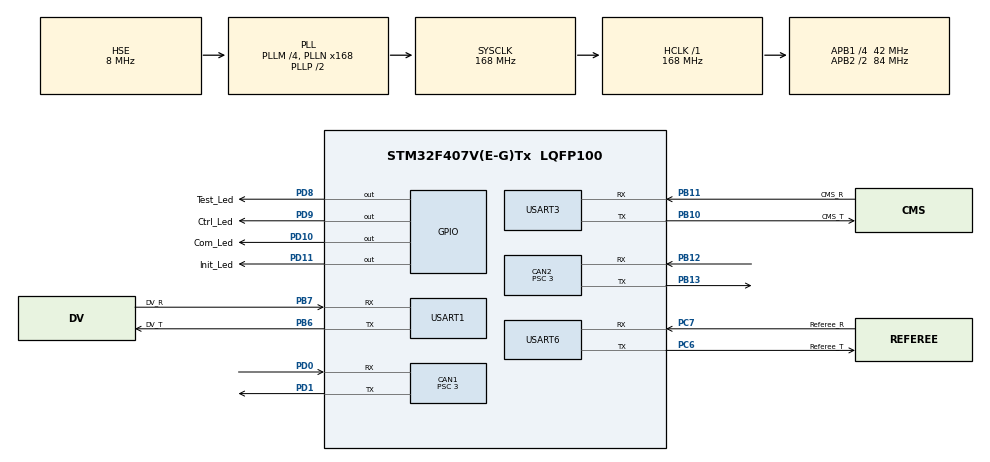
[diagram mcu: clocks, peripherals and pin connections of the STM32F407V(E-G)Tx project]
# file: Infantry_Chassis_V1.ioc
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CAN1.BS1=CAN_BS1_10TQ
CAN1.BS2=CAN_BS2_3TQ
CAN1.CalculateBaudRate=1000000
CAN1.CalculateTimeBit=1000
CAN1.CalculateTimeQuantum=71.42857142857143
CAN1.Prescaler=3
CAN2.BS1=CAN_BS1_10TQ
CAN2.BS2=CAN_BS2_3TQ
CAN2.CalculateBaudRate=1000000
CAN2.CalculateTimeBit=1000
CAN2.CalculateTimeQuantum=71.42857142857143
CAN2.Prescaler=3
Dma.Request0=USART3_RX
Dma.Request1=USART3_TX
Dma.Request2=USART6_RX
Dma.Request3=USART6_TX
Dma.Request4=USART1_TX
Dma.Request5=USART1_RX
Dma.USART1_RX.5.Direction=DMA_PERIPH_TO_MEMORY
Dma.USART1_RX.5.FIFOMode=DMA_FIFOMODE_DISABLE
Dma.USART1_RX.5.Instance=DMA2_Stream2
Dma.USART1_RX.5.MemDataAlignment=DMA_MDATAALIGN_BYTE
Dma.USART1_RX.5.MemInc=DMA_MINC_ENABLE
Dma.USART1_RX.5.Mode=DMA_NORMAL
Dma.USART1_RX.5.PeriphDataAlignment=DMA_PDATAALIGN_BYTE
Dma.USART1_RX.5.PeriphInc=DMA_PINC_DISABLE
Dma.USART1_RX.5.Priority=DMA_PRIORITY_LOW
Dma.USART1_TX.4.Direction=DMA_MEMORY_TO_PERIPH
Dma.USART1_TX.4.FIFOMode=DMA_FIFOMODE_DISABLE
Dma.USART1_TX.4.Instance=DMA2_Stream7
Dma.USART1_TX.4.MemDataAlignment=DMA_MDATAALIGN_BYTE
Dma.USART1_TX.4.MemInc=DMA_MINC_ENABLE
Dma.USART1_TX.4.Mode=DMA_NORMAL
Dma.USART1_TX.4.PeriphDataAlignment=DMA_PDATAALIGN_BYTE
Dma.USART1_TX.4.PeriphInc=DMA_PINC_DISABLE
Dma.USART1_TX.4.Priority=DMA_PRIORITY_LOW
Dma.USART3_RX.0.Direction=DMA_PERIPH_TO_MEMORY
Dma.USART3_RX.0.FIFOMode=DMA_FIFOMODE_DISABLE
Dma.USART3_RX.0.Instance=DMA1_Stream1
Dma.USART3_RX.0.MemDataAlignment=DMA_MDATAALIGN_BYTE
Dma.USART3_RX.0.MemInc=DMA_MINC_ENABLE
Dma.USART3_RX.0.Mode=DMA_NORMAL
Dma.USART3_RX.0.PeriphDataAlignment=DMA_PDATAALIGN_BYTE
Dma.USART3_RX.0.PeriphInc=DMA_PINC_DISABLE
Dma.USART3_RX.0.Priority=DMA_PRIORITY_LOW
Dma.USART3_TX.1.Direction=DMA_MEMORY_TO_PERIPH
Dma.USART3_TX.1.FIFOMode=DMA_FIFOMODE_DISABLE
Dma.USART3_TX.1.Instance=DMA1_Stream3
Dma.USART3_TX.1.MemDataAlignment=DMA_MDATAALIGN_BYTE
Dma.USART3_TX.1.MemInc=DMA_MINC_ENABLE
Dma.USART3_TX.1.Mode=DMA_NORMAL
Dma.USART3_TX.1.PeriphDataAlignment=DMA_PDATAALIGN_BYTE
Dma.USART3_TX.1.PeriphInc=DMA_PINC_DISABLE
Dma.USART3_TX.1.Priority=DMA_PRIORITY_LOW
Dma.USART6_RX.2.Direction=DMA_PERIPH_TO_MEMORY
Dma.USART6_RX.2.FIFOMode=DMA_FIFOMODE_DISABLE
Dma.USART6_RX.2.Instance=DMA2_Stream1
Dma.USART6_RX.2.MemDataAlignment=DMA_MDATAALIGN_BYTE
Dma.USART6_RX.2.MemInc=DMA_MINC_ENABLE
Dma.USART6_RX.2.Mode=DMA_NORMAL
Dma.USART6_RX.2.PeriphDataAlignment=DMA_PDATAALIGN_BYTE
Dma.USART6_RX.2.PeriphInc=DMA_PINC_DISABLE
Dma.USART6_RX.2.Priority=DMA_PRIORITY_LOW
Dma.USART6_TX.3.Direction=DMA_MEMORY_TO_PERIPH
Dma.USART6_TX.3.FIFOMode=DMA_FIFOMODE_DISABLE
Dma.USART6_TX.3.Instance=DMA2_Stream6
Dma.USART6_TX.3.MemDataAlignment=DMA_MDATAALIGN_BYTE
Dma.USART6_TX.3.MemInc=DMA_MINC_ENABLE
Dma.USART6_TX.3.Mode=DMA_NORMAL
Dma.USART6_TX.3.PeriphDataAlignment=DMA_PDATAALIGN_BYTE
Dma.USART6_TX.3.PeriphInc=DMA_PINC_DISABLE
Dma.USART6_TX.3.Priority=DMA_PRIORITY_LOW
FREERTOS.Tasks01=defaultTask,0,128,StartDefaultTask,Default,NULL,Dynamic,NULL,NULL;Chassis,0,512,ChassisTask,As external,NULL,Dynamic,NULL,NULL;Referee,0,512,RefereeTask,As external,NULL,Dynamic,NULL,NULL;DataVsualizatio,0,512,DVTask,As external,NULL,Dynamic,NULL,NULL;Communication,0,512,ComTask,As external,NULL,Dynamic,NULL,NULL;CanSend,3,512,CanSendTask,As external,NULL,Dynamic,NULL,NULL
Mcu.Family=STM32F4
Mcu.Name=STM32F407V(E-G)Tx
Mcu.Package=LQFP100
NVIC.CAN1_RX0_IRQn=true\:5\:0\:false\:false\:true\:true\:true\:true
NVIC.CAN2_RX0_IRQn=true\:5\:0\:false\:false\:true\:true\:true\:true
NVIC.DMA1_Stream1_IRQn=true\:5\:0\:false\:false\:true\:true\:false\:true
NVIC.DMA1_Stream3_IRQn=true\:5\:0\:false\:false\:true\:true\:false\:true
NVIC.DMA2_Stream1_IRQn=true\:5\:0\:false\:false\:true\:true\:false\:true
NVIC.DMA2_Stream2_IRQn=true\:5\:0\:false\:false\:true\:true\:false\:true
NVIC.DMA2_Stream6_IRQn=true\:5\:0\:false\:false\:true\:true\:false\:true
NVIC.DMA2_Stream7_IRQn=true\:5\:0\:false\:false\:true\:true\:false\:true
NVIC.PriorityGroup=NVIC_PRIORITYGROUP_4
NVIC.TIM3_IRQn=true\:5\:0\:false\:false\:true\:true\:true\:true
NVIC.TIM7_IRQn=true\:15\:0\:false\:false\:false\:false\:false\:true
NVIC.TimeBase=TIM7_IRQn
NVIC.TimeBaseIP=TIM7
NVIC.USART1_IRQn=true\:5\:0\:false\:false\:true\:true\:true\:true
NVIC.USART3_IRQn=true\:5\:0\:false\:false\:false\:true\:true\:true
NVIC.USART6_IRQn=true\:5\:0\:false\:false\:false\:true\:true\:true
PA13.Mode=Serial_Wire
PA13.Signal=SYS_JTMS-SWDIO
PA14.Mode=Serial_Wire
PA14.Signal=SYS_JTCK-SWCLK
PB10.GPIO_Label=CMS_T
PB10.Mode=Asynchronous
PB10.Signal=USART3_TX
PB11.GPIO_Label=CMS_R
PB11.Mode=Asynchronous
PB11.Signal=USART3_RX
PB12.Mode=CAN_Activate
PB12.Signal=CAN2_RX
PB13.Mode=CAN_Activate
PB13.Signal=CAN2_TX
PB6.GPIO_Label=DV_T
PB6.Mode=Asynchronous
PB6.Signal=USART1_TX
PB7.GPIO_Label=DV_R
PB7.Mode=Asynchronous
PB7.Signal=USART1_RX
PC6.GPIO_Label=Referee_T
PC6.Mode=Asynchronous
PC6.Signal=USART6_TX
PC7.GPIO_Label=Referee_R
PC7.Mode=Asynchronous
PC7.Signal=USART6_RX
PD0.Mode=CAN_Activate
PD0.Signal=CAN1_RX
PD1.Mode=CAN_Activate
PD1.Signal=CAN1_TX
PD10.GPIO_Label=Com_Led
PD10.Signal=GPIO_Output
PD11.GPIO_Label=Init_Led
PD11.Signal=GPIO_Output
PD8.GPIO_Label=Test_Led
PD8.Signal=GPIO_Output
PD9.GPIO_Label=Ctrl_Led
PD9.Signal=GPIO_Output
PH0-OSC_IN.Mode=HSE-External-Oscillator
PH0-OSC_IN.Signal=RCC_OSC_IN
PH1-OSC_OUT.Mode=HSE-External-Oscillator
PH1-OSC_OUT.Signal=RCC_OSC_OUT
ProjectManager.HeapSize=0x2000
ProjectManager.StackSize=0x2000
ProjectManager.TargetToolchain=MDK-ARM V5.32
RCC.48MHZClocksFreq_Value=84000000
RCC.AHBFreq_Value=168000000
RCC.APB1CLKDivider=RCC_HCLK_DIV4
RCC.APB1Freq_Value=42000000
RCC.APB1TimFreq_Value=84000000
RCC.APB2CLKDivider=RCC_HCLK_DIV2
RCC.APB2Freq_Value=84000000
RCC.APB2TimFreq_Value=168000000
RCC.CortexFreq_Value=168000000
RCC.HCLKFreq_Value=168000000
RCC.HSE_VALUE=8000000
RCC.HSI_VALUE=16000000
RCC.LSE_VALUE=32768
RCC.PLLM=4
RCC.PLLN=168
RCC.PLLSourceVirtual=RCC_PLLSOURCE_HSE
RCC.SYSCLKFreq_VALUE=168000000
RCC.SYSCLKSource=RCC_SYSCLKSOURCE_PLLCLK
RCC.VCOOutputFreq_Value=336000000
TIM3.Period=999
TIM3.Prescaler=83
USART1.VirtualMode=VM_ASYNC
USART3.VirtualMode=VM_ASYNC
USART6.VirtualMode=VM_ASYNC
VP_FREERTOS_VS_CMSIS_V1.Mode=CMSIS_V1
VP_SYS_VS_tim7.Mode=TIM7
VP_TIM3_VS_ClockSourceINT.Mode=Internal
board=custom

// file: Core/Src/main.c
/* USER CODE BEGIN Header */
/**
  ******************************************************************************
  * @file           : main.c
  * @brief          : Main program body
  ******************************************************************************
  * @attention
  *
  * Copyright (c) 2022 STMicroelectronics.
  * All rights reserved.
  *
  * This software is licensed under terms that can be found in the LICENSE file
  * in the root directory of this software component.
  * If no LICENSE file comes with this software, it is provided AS-IS.
  *
  ******************************************************************************
  */
/* USER CODE END Header */
#include "main.h"
#include "cmsis_os.h"
#include "can.h"
#include "dma.h"
#include "tim.h"
#include "usart.h"
#include "gpio.h"

/* USER CODE BEGIN Includes */
#include "CMSInterface.h"
#include "CanReceiveDecom.h"
/* USER CODE END Includes */

void SystemClock_Config(void);
void MX_FREERTOS_Init(void);

int main(void)
{

  /* MCU Configuration--------------------------------------------------------*/

  /* Reset of all peripherals, Initializes the Flash interface and the Systick. */
  HAL_Init();

  /* Configure the system clock */
  SystemClock_Config();

  /* Initialize all configured peripherals */
  MX_GPIO_Init();
  MX_DMA_Init();
  MX_CAN1_Init();
  MX_CAN2_Init();
  MX_USART3_UART_Init();
  MX_USART6_UART_Init();
  MX_USART1_UART_Init();
  MX_TIM3_Init();
  /* USER CODE BEGIN 2 */
//  ComLedError();
can_filter_init();
CMS_usart_init();
USER_CMS_init(&huart3, &CMS_Hub, &hdma_usart3_tx, &hdma_usart3_rx);
  /* USER CODE END 2 */

  /* Call init function for freertos objects (in freertos.c) */
  MX_FREERTOS_Init();
  /* Start scheduler */
  osKernelStart();

  /* We should never get here as control is now taken by the scheduler */
  /* Infinite loop */
  while (1)
  {

  }
}

void SystemClock_Config(void)
{
  RCC_OscInitTypeDef RCC_OscInitStruct = {0};
  RCC_ClkInitTypeDef RCC_ClkInitStruct = {0};

  /** Configure the main internal regulator output voltage
  */
  __HAL_RCC_PWR_CLK_ENABLE();
  __HAL_PWR_VOLTAGESCALING_CONFIG(PWR_REGULATOR_VOLTAGE_SCALE1);
  /** Initializes the RCC Oscillators according to the specified parameters
  * in the RCC_OscInitTypeDef structure.
  */
  RCC_OscInitStruct.OscillatorType = RCC_OSCILLATORTYPE_HSE;
  RCC_OscInitStruct.HSEState = RCC_HSE_ON;
  RCC_OscInitStruct.PLL.PLLState = RCC_PLL_ON;
  RCC_OscInitStruct.PLL.PLLSource = RCC_PLLSOURCE_HSE;
  RCC_OscInitStruct.PLL.PLLM = 4;
  RCC_OscInitStruct.PLL.PLLN = 168;
  RCC_OscInitStruct.PLL.PLLP = RCC_PLLP_DIV2;
  RCC_OscInitStruct.PLL.PLLQ = 4;
  if (HAL_RCC_OscConfig(&RCC_OscInitStruct) != HAL_OK)
  {
    Error_Handler();
  }
  /** Initializes the CPU, AHB and APB buses clocks
  */
  RCC_ClkInitStruct.ClockType = RCC_CLOCKTYPE_HCLK|RCC_CLOCKTYPE_SYSCLK
                              |RCC_CLOCKTYPE_PCLK1|RCC_CLOCKTYPE_PCLK2;
  RCC_ClkInitStruct.SYSCLKSource = RCC_SYSCLKSOURCE_PLLCLK;
  RCC_ClkInitStruct.AHBCLKDivider = RCC_SYSCLK_DIV1;
  RCC_ClkInitStruct.APB1CLKDivider = RCC_HCLK_DIV4;
  RCC_ClkInitStruct.APB2CLKDivider = RCC_HCLK_DIV2;

  if (HAL_RCC_ClockConfig(&RCC_ClkInitStruct, FLASH_LATENCY_5) != HAL_OK)
  {
    Error_Handler();
  }
}

void Error_Handler(void)
{
  __disable_irq();
  while (1)
  {
  }
}

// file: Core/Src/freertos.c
/* USER CODE BEGIN Header */
/**
  ******************************************************************************
  * File Name          : freertos.c
  * Description        : Code for freertos applications
  ******************************************************************************
  * @attention
  *
  * Copyright (c) 2022 STMicroelectronics.
  * All rights reserved.
  *
  * This software is licensed under terms that can be found in the LICENSE file
  * in the root directory of this software component.
  * If no LICENSE file comes with this software, it is provided AS-IS.
  *
  ******************************************************************************
  */
/* USER CODE END Header */

#include "FreeRTOS.h"
#include "task.h"
#include "main.h"
#include "cmsis_os.h"

osThreadId defaultTaskHandle;
osThreadId ChassisHandle;
osThreadId RefereeHandle;
osThreadId DataVsualizatioHandle;
osThreadId CommunicationHandle;
osThreadId CanSendHandle;

void StartDefaultTask(void const * argument);
extern void ChassisTask(void const * argument);
extern void RefereeTask(void const * argument);
extern void DVTask(void const * argument);
extern void ComTask(void const * argument);
extern void CanSendTask(void const * argument);

void MX_FREERTOS_Init(void); /* (MISRA C 2004 rule 8.1) */

/* GetIdleTaskMemory prototype (linked to static allocation support) */
void vApplicationGetIdleTaskMemory( StaticTask_t **ppxIdleTaskTCBBuffer, StackType_t **ppxIdleTaskStackBuffer, uint32_t *pulIdleTaskStackSize );

/* USER CODE BEGIN GET_IDLE_TASK_MEMORY */
static StaticTask_t xIdleTaskTCBBuffer;
static StackType_t xIdleStack[configMINIMAL_STACK_SIZE];

void vApplicationGetIdleTaskMemory( StaticTask_t **ppxIdleTaskTCBBuffer, StackType_t **ppxIdleTaskStackBuffer, uint32_t *pulIdleTaskStackSize )
{
  *ppxIdleTaskTCBBuffer = &xIdleTaskTCBBuffer;
  *ppxIdleTaskStackBuffer = &xIdleStack[0];
  *pulIdleTaskStackSize = configMINIMAL_STACK_SIZE;
  /* place for user code */
}
/* USER CODE END GET_IDLE_TASK_MEMORY */

void MX_FREERTOS_Init(void) {

  /* Create the thread(s) */
  /* definition and creation of defaultTask */
  osThreadDef(defaultTask, StartDefaultTask, osPriorityNormal, 0, 128);
  defaultTaskHandle = osThreadCreate(osThread(defaultTask), NULL);

  /* definition and creation of Chassis */
  osThreadDef(Chassis, ChassisTask, osPriorityNormal, 0, 512);
  ChassisHandle = osThreadCreate(osThread(Chassis), NULL);

  /* definition and creation of Referee */
  osThreadDef(Referee, RefereeTask, osPriorityNormal, 0, 512);
  RefereeHandle = osThreadCreate(osThread(Referee), NULL);

  /* definition and creation of DataVsualizatio */
  osThreadDef(DataVsualizatio, DVTask, osPriorityNormal, 0, 512);
  DataVsualizatioHandle = osThreadCreate(osThread(DataVsualizatio), NULL);

  /* definition and creation of Communication */
  osThreadDef(Communication, ComTask, osPriorityNormal, 0, 512);
  CommunicationHandle = osThreadCreate(osThread(Communication), NULL);

  /* definition and creation of CanSend */
  osThreadDef(CanSend, CanSendTask, osPriorityRealtime, 0, 512);
  CanSendHandle = osThreadCreate(osThread(CanSend), NULL);

}

void StartDefaultTask(void const * argument)
{
  for(;;)
  {
    osDelay(1);
  }
}
